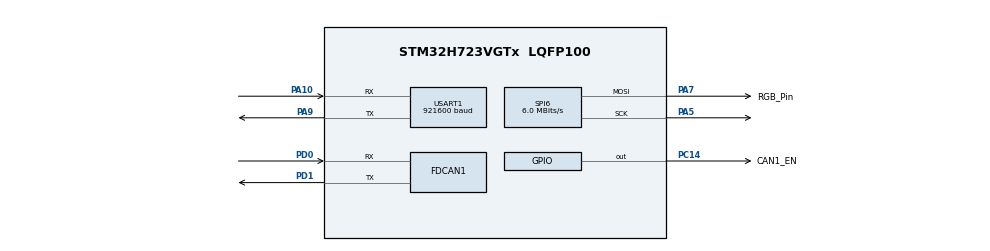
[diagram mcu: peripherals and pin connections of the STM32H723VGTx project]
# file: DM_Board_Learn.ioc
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CORTEX_M7.default_mode_Activation=1
Dma.Request0=USART1_RX
Dma.Request1=USART1_TX
Dma.USART1_RX.0.Direction=DMA_PERIPH_TO_MEMORY
Dma.USART1_RX.0.EventEnable=DISABLE
Dma.USART1_RX.0.FIFOMode=DMA_FIFOMODE_DISABLE
Dma.USART1_RX.0.Instance=DMA1_Stream0
Dma.USART1_RX.0.MemDataAlignment=DMA_MDATAALIGN_BYTE
Dma.USART1_RX.0.MemInc=DMA_MINC_ENABLE
Dma.USART1_RX.0.Mode=DMA_CIRCULAR
Dma.USART1_RX.0.PeriphDataAlignment=DMA_PDATAALIGN_BYTE
Dma.USART1_RX.0.PeriphInc=DMA_PINC_DISABLE
Dma.USART1_RX.0.Polarity=HAL_DMAMUX_REQ_GEN_RISING
Dma.USART1_RX.0.Priority=DMA_PRIORITY_MEDIUM
Dma.USART1_RX.0.RequestNumber=1
Dma.USART1_RX.0.SignalID=NONE
Dma.USART1_RX.0.SyncEnable=DISABLE
Dma.USART1_RX.0.SyncPolarity=HAL_DMAMUX_SYNC_NO_EVENT
Dma.USART1_RX.0.SyncRequestNumber=1
Dma.USART1_RX.0.SyncSignalID=NONE
Dma.USART1_TX.1.Direction=DMA_MEMORY_TO_PERIPH
Dma.USART1_TX.1.EventEnable=DISABLE
Dma.USART1_TX.1.FIFOMode=DMA_FIFOMODE_DISABLE
Dma.USART1_TX.1.Instance=DMA1_Stream1
Dma.USART1_TX.1.MemDataAlignment=DMA_MDATAALIGN_BYTE
Dma.USART1_TX.1.MemInc=DMA_MINC_ENABLE
Dma.USART1_TX.1.Mode=DMA_NORMAL
Dma.USART1_TX.1.PeriphDataAlignment=DMA_PDATAALIGN_BYTE
Dma.USART1_TX.1.PeriphInc=DMA_PINC_DISABLE
Dma.USART1_TX.1.Polarity=HAL_DMAMUX_REQ_GEN_RISING
Dma.USART1_TX.1.Priority=DMA_PRIORITY_MEDIUM
Dma.USART1_TX.1.RequestNumber=1
Dma.USART1_TX.1.SignalID=NONE
Dma.USART1_TX.1.SyncEnable=DISABLE
Dma.USART1_TX.1.SyncPolarity=HAL_DMAMUX_SYNC_NO_EVENT
Dma.USART1_TX.1.SyncRequestNumber=1
Dma.USART1_TX.1.SyncSignalID=NONE
FDCAN1.CalculateBaudRateNominal=1000000
FDCAN1.CalculateTimeBitNominal=1000
FDCAN1.CalculateTimeQuantumNominal=100.0
FDCAN1.DataPrescaler=10
FDCAN1.DataTimeSeg1=6
FDCAN1.DataTimeSeg2=3
FDCAN1.MessageRAMOffset=0
FDCAN1.NominalPrescaler=10
FDCAN1.NominalTimeSeg1=6
FDCAN1.NominalTimeSeg2=3
FDCAN1.ProtocolException=DISABLE
FDCAN1.RxFifo0ElmtsNbr=8
FDCAN1.RxFifo1ElmtsNbr=8
FDCAN1.TxFifoQueueElmtsNbr=8
Mcu.Family=STM32H7
Mcu.Name=STM32H723VGTx
Mcu.Package=LQFP100
NVIC.DMA1_Stream0_IRQn=true\:0\:0\:false\:false\:true\:false\:true\:true
NVIC.DMA1_Stream1_IRQn=true\:0\:0\:false\:false\:true\:false\:true\:true
NVIC.FDCAN1_IT0_IRQn=true\:0\:0\:false\:false\:true\:true\:true\:true
NVIC.FDCAN1_IT1_IRQn=true\:0\:0\:false\:false\:true\:true\:true\:true
NVIC.FDCAN_CAL_IRQn=true\:0\:0\:false\:false\:true\:true\:true\:true
NVIC.PriorityGroup=NVIC_PRIORITYGROUP_4
NVIC.USART1_IRQn=true\:0\:0\:false\:false\:true\:true\:true\:true
PA10.Mode=Asynchronous
PA10.Signal=USART1_RX
PA13(JTMS/SWDIO).Mode=Serial_Wire
PA13(JTMS/SWDIO).Signal=DEBUG_JTMS-SWDIO
PA14(JTCK/SWCLK).Mode=Serial_Wire
PA14(JTCK/SWCLK).Signal=DEBUG_JTCK-SWCLK
PA5.GPIO_Speed=GPIO_SPEED_FREQ_VERY_HIGH
PA5.Mode=TX_Only_Simplex_Unidirect_Master
PA5.Signal=SPI6_SCK
PA7.GPIO_Label=RGB_Pin
PA7.GPIO_Speed=GPIO_SPEED_FREQ_VERY_HIGH
PA7.Mode=TX_Only_Simplex_Unidirect_Master
PA7.Signal=SPI6_MOSI
PA9.GPIO_ModeDefaultPP=GPIO_MODE_AF_PP
PA9.GPIO_PuPd=GPIO_NOPULL
PA9.GPIO_Speed=GPIO_SPEED_FREQ_LOW
PA9.Mode=Asynchronous
PA9.Signal=USART1_TX
PC14-OSC32_IN.GPIO_Label=CAN1_EN
PC14-OSC32_IN.GPIO_PuPd=GPIO_PULLUP
PC14-OSC32_IN.Signal=GPIO_Output
PD0.Mode=FDCAN_Activate
PD0.Signal=FDCAN1_RX
PD1.Mode=FDCAN_Activate
PD1.Signal=FDCAN1_TX
PH0-OSC_IN.Mode=HSE-External-Oscillator
PH0-OSC_IN.Signal=RCC_OSC_IN
PH1-OSC_OUT.Mode=HSE-External-Oscillator
PH1-OSC_OUT.Signal=RCC_OSC_OUT
ProjectManager.HeapSize=0x200
ProjectManager.StackSize=0x400
ProjectManager.TargetToolchain=STM32CubeIDE
RCC.ADCFreq_Value=48375000
RCC.APB1Freq_Value=125000000
RCC.APB2Freq_Value=125000000
RCC.APB3Freq_Value=125000000
RCC.APB4Freq_Value=125000000
RCC.CortexFreq_Value=500000000
RCC.D1PPRE=RCC_APB3_DIV2
RCC.D2PPRE1=RCC_APB1_DIV2
RCC.D2PPRE2=RCC_APB2_DIV2
RCC.D3PPRE=RCC_APB4_DIV2
RCC.DIVM1=3
RCC.DIVN1=62
RCC.DIVP1=1
RCC.DIVQ1=5
RCC.HCLKFreq_Value=250000000
RCC.HPRE=RCC_HCLK_DIV2
RCC.HSE_VALUE=24000000
RCC.PLL2FRACN=0
RCC.PLL3FRACN=0
RCC.PLLFRACN=4096
RCC.PLLSourceVirtual=RCC_PLLSOURCE_HSE
RCC.SPI6CLockSelection=RCC_SPI6CLKSOURCE_HSE
RCC.SYSCLKFreq_VALUE=500000000
RCC.SYSCLKSource=RCC_SYSCLKSOURCE_PLLCLK
RCC.USBFreq_Value=100000000
SPI6.BaudRatePrescaler=SPI_BAUDRATEPRESCALER_4
SPI6.CLKPhase=SPI_PHASE_2EDGE
SPI6.CalculateBaudRate=6.0 MBits/s
SPI6.DataSize=SPI_DATASIZE_8BIT
SPI6.Direction=SPI_DIRECTION_2LINES_TXONLY
SPI6.Mode=SPI_MODE_MASTER
SPI6.VirtualType=VM_MASTER
USART1.BaudRate=921600
USART1.VirtualMode-Asynchronous=VM_ASYNC
VP_MEMORYMAP_VS_MEMORYMAP.Mode=CurAppReg
board=custom

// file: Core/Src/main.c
/* USER CODE BEGIN Header */
/**
  ******************************************************************************
  * @file           : main.c
  * @brief          : Main program body
  ******************************************************************************
  * @attention
  *
  * Copyright (c) 2025 STMicroelectronics.
  * All rights reserved.
  *
  * This software is licensed under terms that can be found in the LICENSE file
  * in the root directory of this software component.
  * If no LICENSE file comes with this software, it is provided AS-IS.
  *
  ******************************************************************************
  */
/* USER CODE END Header */
#include "main.h"
#include "dma.h"
#include "fdcan.h"
#include "memorymap.h"
#include "spi.h"
#include "usart.h"
#include "gpio.h"

/* USER CODE BEGIN Includes */
#include "a_SysManager.h"
/* USER CODE END Includes */

void SystemClock_Config(void);
static void MPU_Config(void);

int main(void)
{

  /* MPU Configuration--------------------------------------------------------*/
  MPU_Config();

  /* MCU Configuration--------------------------------------------------------*/

  /* Reset of all peripherals, Initializes the Flash interface and the Systick. */
  HAL_Init();

  /* Configure the system clock */
  SystemClock_Config();

  /* Initialize all configured peripherals */
  MX_GPIO_Init();
  MX_DMA_Init();
  MX_USART1_UART_Init();
  MX_SPI6_Init();
  MX_FDCAN1_Init();
  /* USER CODE BEGIN 2 */
    SysManager_Init();
  /* USER CODE END 2 */

  /* Infinite loop */
  /* USER CODE BEGIN WHILE */
  while (1)
  {
    SysManager_Process();
    /* USER CODE END WHILE */

  }
}

void SystemClock_Config(void)
{
  RCC_OscInitTypeDef RCC_OscInitStruct = {0};
  RCC_ClkInitTypeDef RCC_ClkInitStruct = {0};

  /** Supply configuration update enable
  */
  HAL_PWREx_ConfigSupply(PWR_LDO_SUPPLY);

  /** Configure the main internal regulator output voltage
  */
  __HAL_PWR_VOLTAGESCALING_CONFIG(PWR_REGULATOR_VOLTAGE_SCALE0);

  while(!__HAL_PWR_GET_FLAG(PWR_FLAG_VOSRDY)) {}

  /** Initializes the RCC Oscillators according to the specified parameters
  * in the RCC_OscInitTypeDef structure.
  */
  RCC_OscInitStruct.OscillatorType = RCC_OSCILLATORTYPE_HSE;
  RCC_OscInitStruct.HSEState = RCC_HSE_ON;
  RCC_OscInitStruct.PLL.PLLState = RCC_PLL_ON;
  RCC_OscInitStruct.PLL.PLLSource = RCC_PLLSOURCE_HSE;
  RCC_OscInitStruct.PLL.PLLM = 3;
  RCC_OscInitStruct.PLL.PLLN = 62;
  RCC_OscInitStruct.PLL.PLLP = 1;
  RCC_OscInitStruct.PLL.PLLQ = 5;
  RCC_OscInitStruct.PLL.PLLR = 2;
  RCC_OscInitStruct.PLL.PLLRGE = RCC_PLL1VCIRANGE_3;
  RCC_OscInitStruct.PLL.PLLVCOSEL = RCC_PLL1VCOWIDE;
  RCC_OscInitStruct.PLL.PLLFRACN = 4096;
  if (HAL_RCC_OscConfig(&RCC_OscInitStruct) != HAL_OK)
  {
    Error_Handler();
  }

  /** Initializes the CPU, AHB and APB buses clocks
  */
  RCC_ClkInitStruct.ClockType = RCC_CLOCKTYPE_HCLK|RCC_CLOCKTYPE_SYSCLK
                              |RCC_CLOCKTYPE_PCLK1|RCC_CLOCKTYPE_PCLK2
                              |RCC_CLOCKTYPE_D3PCLK1|RCC_CLOCKTYPE_D1PCLK1;
  RCC_ClkInitStruct.SYSCLKSource = RCC_SYSCLKSOURCE_PLLCLK;
  RCC_ClkInitStruct.SYSCLKDivider = RCC_SYSCLK_DIV1;
  RCC_ClkInitStruct.AHBCLKDivider = RCC_HCLK_DIV2;
  RCC_ClkInitStruct.APB3CLKDivider = RCC_APB3_DIV2;
  RCC_ClkInitStruct.APB1CLKDivider = RCC_APB1_DIV2;
  RCC_ClkInitStruct.APB2CLKDivider = RCC_APB2_DIV2;
  RCC_ClkInitStruct.APB4CLKDivider = RCC_APB4_DIV2;

  if (HAL_RCC_ClockConfig(&RCC_ClkInitStruct, FLASH_LATENCY_3) != HAL_OK)
  {
    Error_Handler();
  }
}

 /* MPU Configuration */

void MPU_Config(void)
{
  MPU_Region_InitTypeDef MPU_InitStruct = {0};

  /* Disables the MPU */
  HAL_MPU_Disable();

  /** Initializes and configures the Region and the memory to be protected
  */
  MPU_InitStruct.Enable = MPU_REGION_ENABLE;
  MPU_InitStruct.Number = MPU_REGION_NUMBER0;
  MPU_InitStruct.BaseAddress = 0x0;
  MPU_InitStruct.Size = MPU_REGION_SIZE_4GB;
  MPU_InitStruct.SubRegionDisable = 0x87;
  MPU_InitStruct.TypeExtField = MPU_TEX_LEVEL0;
  MPU_InitStruct.AccessPermission = MPU_REGION_NO_ACCESS;
  MPU_InitStruct.DisableExec = MPU_INSTRUCTION_ACCESS_DISABLE;
  MPU_InitStruct.IsShareable = MPU_ACCESS_SHAREABLE;
  MPU_InitStruct.IsCacheable = MPU_ACCESS_NOT_CACHEABLE;
  MPU_InitStruct.IsBufferable = MPU_ACCESS_NOT_BUFFERABLE;

  HAL_MPU_ConfigRegion(&MPU_InitStruct);
  /* Enables the MPU */
  HAL_MPU_Enable(MPU_PRIVILEGED_DEFAULT);

}

void Error_Handler(void)
{
  __disable_irq();
  while (1)
  {
  }
}
